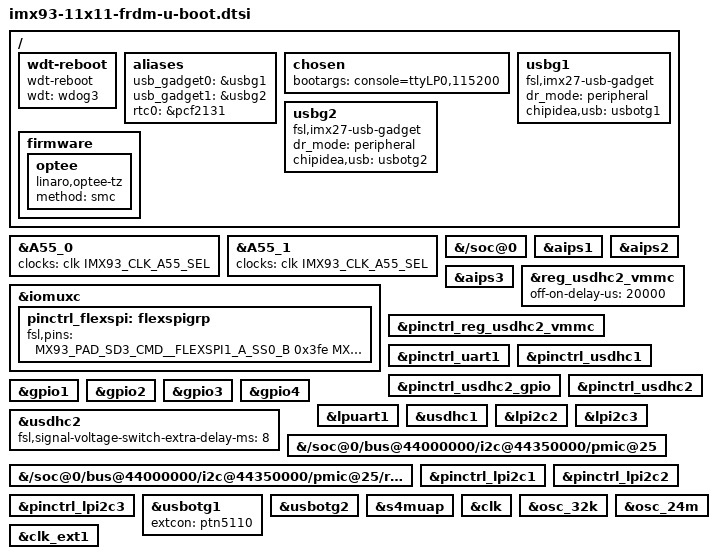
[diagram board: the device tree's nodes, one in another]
// SPDX-License-Identifier: GPL-2.0+
/*
 * Copyright 2025 NXP
 */

#include "imx93-u-boot.dtsi"

/ {
	wdt-reboot {
		compatible = "wdt-reboot";
		wdt = <&wdog3>;
		bootph-pre-ram;
		bootph-some-ram;
	};

	aliases {
		usb_gadget0 = &usbg1;
		usb_gadget1 = &usbg2;
		rtc0 = &pcf2131;
	};

	chosen {
		bootargs = "console=ttyLP0,115200";
	};

	usbg1: usbg1 {
		compatible = "fsl,imx27-usb-gadget";
		dr_mode = "peripheral";
		chipidea,usb = <&usbotg1>;
		status = "okay";
	};

	usbg2: usbg2 {
		compatible = "fsl,imx27-usb-gadget";
		dr_mode = "peripheral";
		chipidea,usb = <&usbotg2>;
		status = "okay";
	};

	firmware {
		optee {
			compatible = "linaro,optee-tz";
			method = "smc";
		};
	};
};

&A55_0 {
	clocks = <&clk IMX93_CLK_A55_SEL>;
};

&A55_1 {
	clocks = <&clk IMX93_CLK_A55_SEL>;
};

&{/soc@0} {
	bootph-all;
	bootph-pre-ram;
};

&aips1 {
	bootph-pre-ram;
	bootph-all;
};

&aips2 {
	bootph-pre-ram;
	bootph-some-ram;
};

&aips3 {
	bootph-pre-ram;
	bootph-some-ram;
};

&iomuxc {
	bootph-pre-ram;
	bootph-some-ram;

	pinctrl_flexspi: flexspigrp {
		fsl,pins = <
			MX93_PAD_SD3_CMD__FLEXSPI1_A_SS0_B      0x3fe
			MX93_PAD_SD3_CLK__FLEXSPI1_A_SCLK       0x3fe
			MX93_PAD_SD3_DATA0__FLEXSPI1_A_DATA00   0x3fe
			MX93_PAD_SD3_DATA1__FLEXSPI1_A_DATA01   0x3fe
			MX93_PAD_SD3_DATA2__FLEXSPI1_A_DATA02   0x3fe
			MX93_PAD_SD3_DATA3__FLEXSPI1_A_DATA03   0x3fe
		>;
	};
};

&reg_usdhc2_vmmc {
	off-on-delay-us = <20000>;
	bootph-pre-ram;
};

&pinctrl_reg_usdhc2_vmmc {
	bootph-pre-ram;
};

&pinctrl_uart1 {
	bootph-pre-ram;
	bootph-some-ram;
};

&pinctrl_usdhc1 {
	bootph-pre-ram;
};

&pinctrl_usdhc2_gpio {
	bootph-pre-ram;
};

&pinctrl_usdhc2 {
	bootph-pre-ram;
};

&gpio1 {
	bootph-pre-ram;
	bootph-some-ram;
};

&gpio2 {
	bootph-pre-ram;
	bootph-some-ram;
};

&gpio3 {
	bootph-pre-ram;
	bootph-some-ram;
};

&gpio4 {
	bootph-pre-ram;
	bootph-some-ram;
};

&lpuart1 {
	bootph-pre-ram;
	bootph-some-ram;
};

&usdhc1 {
	bootph-pre-ram;
};

&usdhc2 {
	bootph-pre-ram;
	fsl,signal-voltage-switch-extra-delay-ms = <8>;
};

&lpi2c2 {
	bootph-pre-ram;
};

&lpi2c3 {
	bootph-pre-ram;
};

&{/soc@0/bus@44000000/i2c@44350000/pmic@25} {
	bootph-pre-ram;
};

&{/soc@0/bus@44000000/i2c@44350000/pmic@25/regulators} {
	bootph-pre-ram;
};

&pinctrl_lpi2c1 {
	bootph-pre-ram;
};

&pinctrl_lpi2c2 {
	bootph-pre-ram;
};

&pinctrl_lpi2c3 {
	bootph-pre-ram;
};

&usbotg1 {
	status = "okay";
	extcon = <&ptn5110>;
};

&usbotg2 {
	status = "okay";
};

&s4muap {
	bootph-pre-ram;
	bootph-some-ram;
	status = "okay";
};

&clk {
	bootph-all;
	bootph-pre-ram;
	/delete-property/ assigned-clocks;
	/delete-property/ assigned-clock-rates;
	/delete-property/ assigned-clock-parents;
};

&osc_32k {
	bootph-all;
	bootph-pre-ram;
};

&osc_24m {
	bootph-all;
	bootph-pre-ram;
};

&clk_ext1 {
	bootph-all;
	bootph-pre-ram;
};
